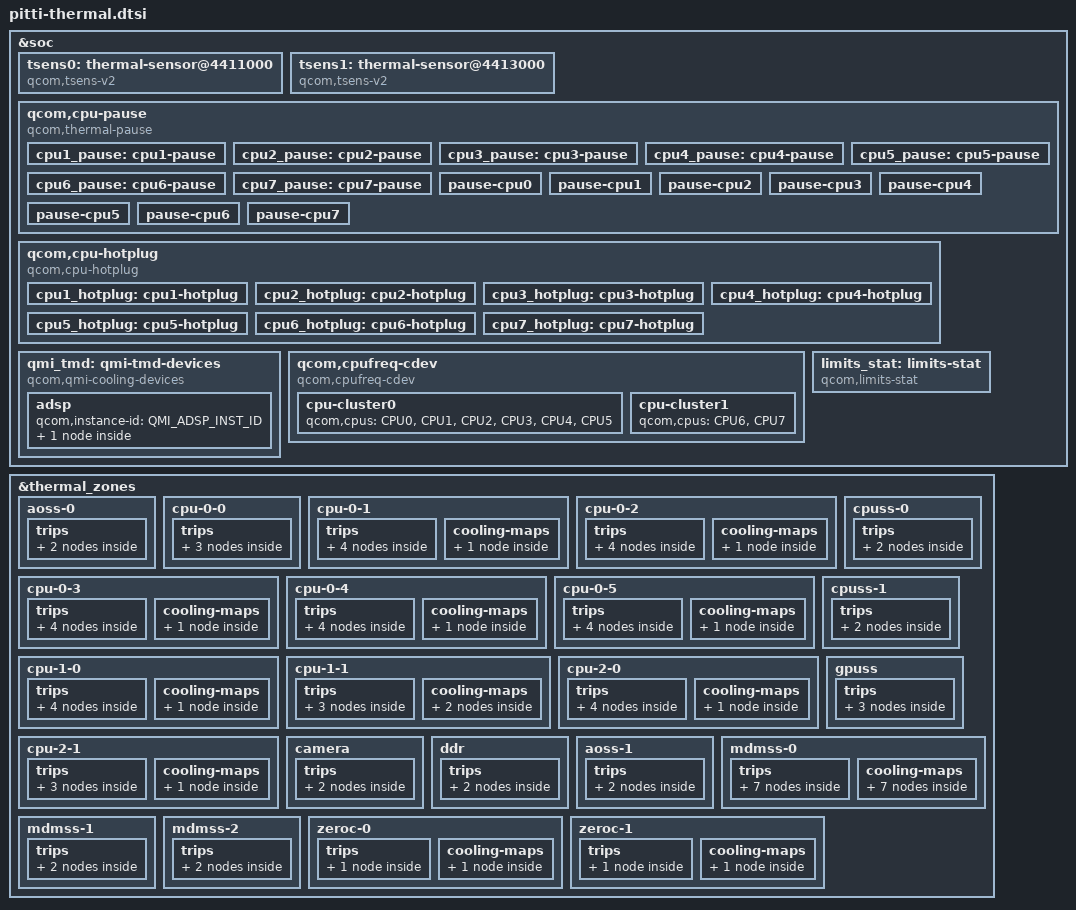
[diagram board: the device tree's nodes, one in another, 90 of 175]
#include <dt-bindings/thermal/thermal_qti.h>

&soc {
	tsens0: thermal-sensor@4411000 {
		compatible = "qcom,tsens-v2";
		reg = <0x04411000 0x1ff>, /* TM */
			<0x04410000 0x1ff>; /* SROT */
		#qcom,sensors = <16>;
		interrupts = <GIC_SPI 275 IRQ_TYPE_LEVEL_HIGH>,
				<GIC_SPI 190 IRQ_TYPE_LEVEL_HIGH>,
				<GIC_SPI 314 IRQ_TYPE_LEVEL_HIGH>;
		interrupt-names = "uplow",
				"critical",
				"cold";
		#thermal-sensor-cells = <1>;
	};

	tsens1: thermal-sensor@4413000 {
		compatible = "qcom,tsens-v2";
		reg = <0x04413000 0x1ff>, /* TM */
			<0x04412000 0x1ff>; /* SROT */
		#qcom,sensors = <4>;
		interrupts = <GIC_SPI 293 IRQ_TYPE_LEVEL_HIGH>,
				<GIC_SPI 316 IRQ_TYPE_LEVEL_HIGH>,
				<GIC_SPI 315 IRQ_TYPE_LEVEL_HIGH>;
		interrupt-names = "uplow",
			"critical",
			"cold";
		#thermal-sensor-cells = <1>;
	};

	qcom,cpu-pause {
		compatible = "qcom,thermal-pause";

		cpu1_pause: cpu1-pause {
			qcom,cpus = <&CPU1>;
			qcom,cdev-alias = "thermal-pause-2";
			#cooling-cells = <2>;
		};

		cpu2_pause: cpu2-pause {
			qcom,cpus = <&CPU2>;
			qcom,cdev-alias = "thermal-pause-4";
			#cooling-cells = <2>;
		};

		cpu3_pause: cpu3-pause {
			qcom,cpus = <&CPU3>;
			qcom,cdev-alias = "thermal-pause-8";
			#cooling-cells = <2>;
		};

		cpu4_pause: cpu4-pause {
			qcom,cpus = <&CPU4>;
			qcom,cdev-alias = "thermal-pause-10";
			#cooling-cells = <2>;
		};

		cpu5_pause: cpu5-pause {
			qcom,cpus = <&CPU5>;
			qcom,cdev-alias = "thermal-pause-20";
			#cooling-cells = <2>;
		};

		cpu6_pause: cpu6-pause {
			qcom,cpus = <&CPU6>;
			qcom,cdev-alias = "thermal-pause-40";
			#cooling-cells = <2>;
		};

		cpu7_pause: cpu7-pause {
			qcom,cpus = <&CPU7>;
			qcom,cdev-alias = "thermal-pause-80";
			#cooling-cells = <2>;
		};

		/* Thermal-engine cooling devices */
		pause-cpu0 {
			qcom,cpus = <&CPU0>;
			qcom,cdev-alias = "pause-cpu0";
		};

		pause-cpu1 {
			qcom,cpus = <&CPU1>;
			qcom,cdev-alias = "pause-cpu1";
		};

		pause-cpu2 {
			qcom,cpus = <&CPU2>;
			qcom,cdev-alias = "pause-cpu2";
		};

		pause-cpu3 {
			qcom,cpus = <&CPU3>;
			qcom,cdev-alias = "pause-cpu3";
		};

		pause-cpu4 {
			qcom,cpus = <&CPU4>;
			qcom,cdev-alias = "pause-cpu4";
		};

		pause-cpu5 {
			qcom,cpus = <&CPU5>;
			qcom,cdev-alias = "pause-cpu5";
		};

		pause-cpu6 {
			qcom,cpus = <&CPU6>;
			qcom,cdev-alias = "pause-cpu6";
		};

		pause-cpu7 {
			qcom,cpus = <&CPU7>;
			qcom,cdev-alias = "pause-cpu7";
		};
	};

	qcom,cpu-hotplug {
		compatible = "qcom,cpu-hotplug";

		cpu1_hotplug: cpu1-hotplug {
			qcom,cpu = <&CPU1>;
			qcom,cdev-alias = "cpu-hotplug1";
			#cooling-cells = <2>;
		};

		cpu2_hotplug: cpu2-hotplug {
			qcom,cpu = <&CPU2>;
			qcom,cdev-alias = "cpu-hotplug2";
			#cooling-cells = <2>;
		};

		cpu3_hotplug: cpu3-hotplug {
			qcom,cpu = <&CPU3>;
			qcom,cdev-alias = "cpu-hotplug3";
			#cooling-cells = <2>;
		};

		cpu4_hotplug: cpu4-hotplug {
			qcom,cpu = <&CPU4>;
			qcom,cdev-alias = "cpu-hotplug4";
			#cooling-cells = <2>;
		};

		cpu5_hotplug: cpu5-hotplug {
			qcom,cpu = <&CPU5>;
			qcom,cdev-alias = "cpu-hotplug5";
			#cooling-cells = <2>;
		};

		cpu6_hotplug: cpu6-hotplug {
			qcom,cpu = <&CPU6>;
			qcom,cdev-alias = "cpu-hotplug6";
			#cooling-cells = <2>;
		};

		cpu7_hotplug: cpu7-hotplug {
			qcom,cpu = <&CPU7>;
			qcom,cdev-alias = "cpu-hotplug7";
			#cooling-cells = <2>;
		};
	};

	qmi_tmd: qmi-tmd-devices {
		compatible = "qcom,qmi-cooling-devices";
		adsp {
			qcom,instance-id = <QMI_ADSP_INST_ID>;

			adsp_vdd: adsp_vdd {
				qcom,qmi-dev-name = "cpuv_restriction_cold";
				#cooling-cells = <2>;
			};
		};
	};

	qcom,cpufreq-cdev {
		compatible = "qcom,cpufreq-cdev";
		cpu-cluster0 {
			qcom,cpus = <&CPU0 &CPU1 &CPU2 &CPU3 &CPU4 &CPU5>;
		};

		cpu-cluster1 {
			qcom,cpus = <&CPU6 &CPU7>;
		};
	};

	limits_stat: limits-stat {
		compatible = "qcom,limits-stat";
		qcom,limits-stat-sensor-names = "aoss-0", "cpu-0-0", "cpu-0-1",
						"cpu-0-2", "cpu-0-3", "cpu-0-4",
						"cpu-0-5", "cpuss-0", "cpuss-1",
						"cpu-1-0", "cpu-1-1", "cpu-2-0",
						"cpu-2-1", "gpuss", "camera",
						"ddr", "aoss-1", "mdmss-0", "mdmss-1",
						"mdmss-2";
	};
};

#include "pitti-thermal-modem.dtsi"

&thermal_zones {
	aoss-0 {
		polling-delay-passive = <0>;
		polling-delay = <0>;
		thermal-sensors = <&tsens0 0>;
		trips {
			thermal-engine-config {
				temperature = <125000>;
				hysteresis = <1000>;
				type = "passive";
			};

			reset-mon-cfg {
				temperature = <115000>;
				hysteresis = <5000>;
				type = "passive";
			};
		};
	};

	cpu-0-0 {
		polling-delay-passive = <0>;
		polling-delay = <0>;
		thermal-sensors = <&tsens0 1>;
		trips {
			thermal-engine-config {
				temperature = <125000>;
				hysteresis = <1000>;
				type = "passive";
			};

			thermal-hal-config {
				temperature = <125000>;
				hysteresis = <1000>;
				type = "passive";
			};

			reset-mon-cfg {
				temperature = <115000>;
				hysteresis = <5000>;
				type = "passive";
			};
		};
	};

	cpu-0-1 {
		polling-delay-passive = <0>;
		polling-delay = <0>;
		thermal-sensors = <&tsens0 2>;
		trips {
			thermal-engine-config {
				temperature = <125000>;
				hysteresis = <1000>;
				type = "passive";
			};

			thermal-hal-config {
				temperature = <125000>;
				hysteresis = <1000>;
				type = "passive";
			};

			reset-mon-cfg {
				temperature = <115000>;
				hysteresis = <5000>;
				type = "passive";
			};

			cpu01_config: cpu01-config {
				temperature = <110000>;
				hysteresis = <10000>;
				type = "passive";
			};
		};

		cooling-maps {
			cpu01_cdev {
				trip = <&cpu01_config>;
				cooling-device = <&cpu1_pause 1 1>;
			};
		};
	};

	cpu-0-2 {
		polling-delay-passive = <0>;
		polling-delay = <0>;
		thermal-sensors = <&tsens0 3>;
		trips {
			thermal-engine-config {
				temperature = <125000>;
				hysteresis = <1000>;
				type = "passive";
			};

			thermal-hal-config {
				temperature = <125000>;
				hysteresis = <1000>;
				type = "passive";
			};

			reset-mon-cfg {
				temperature = <115000>;
				hysteresis = <5000>;
				type = "passive";
			};

			cpu02_config: cpu02-config {
				temperature = <110000>;
				hysteresis = <10000>;
				type = "passive";
			};
		};

		cooling-maps {
			cpu02_cdev {
				trip = <&cpu02_config>;
				cooling-device = <&cpu2_pause 1 1>;
			};
		};
	};

	cpu-0-3 {
		polling-delay-passive = <0>;
		polling-delay = <0>;
		thermal-sensors = <&tsens0 4>;
		trips {
			thermal-engine-config {
				temperature = <125000>;
				hysteresis = <1000>;
				type = "passive";
			};

			thermal-hal-config {
				temperature = <125000>;
				hysteresis = <1000>;
				type = "passive";
			};

			reset-mon-cfg {
				temperature = <115000>;
				hysteresis = <5000>;
				type = "passive";
			};

			cpu03_config: cpu03-config {
				temperature = <110000>;
				hysteresis = <10000>;
				type = "passive";
			};
		};

		cooling-maps {
			cpu03_cdev {
				trip = <&cpu03_config>;
				cooling-device = <&cpu3_pause 1 1>;
			};
		};
	};

	cpu-0-4 {
		polling-delay-passive = <0>;
		polling-delay = <0>;
		thermal-sensors = <&tsens0 5>;
		trips {
			thermal-engine-config {
				temperature = <125000>;
				hysteresis = <1000>;
				type = "passive";
			};

			thermal-hal-config {
				temperature = <125000>;
				hysteresis = <1000>;
				type = "passive";
			};

			reset-mon-cfg {
				temperature = <115000>;
				hysteresis = <5000>;
				type = "passive";
			};

			cpu04_config: cpu04-config {
				temperature = <110000>;
				hysteresis = <10000>;
				type = "passive";
			};
		};

		cooling-maps {
			cpu04_cdev {
				trip = <&cpu04_config>;
				cooling-device = <&cpu4_pause 1 1>;
			};
		};
	};

	cpu-0-5 {
		polling-delay-passive = <0>;
		polling-delay = <0>;
		thermal-sensors = <&tsens0 6>;
		trips {
			thermal-engine-config {
				temperature = <125000>;
				hysteresis = <1000>;
				type = "passive";
			};

			thermal-hal-config {
				temperature = <125000>;
				hysteresis = <1000>;
				type = "passive";
			};

			reset-mon-cfg {
				temperature = <115000>;
				hysteresis = <5000>;
				type = "passive";
			};

			cpu05_config: cpu05-config {
				temperature = <110000>;
				hysteresis = <10000>;
				type = "passive";
			};
		};

		cooling-maps {
			cpu05_cdev {
				trip = <&cpu05_config>;
				cooling-device = <&cpu5_pause 1 1>;
			};
		};
	};

	cpuss-0 {
		polling-delay-passive = <0>;
		polling-delay = <0>;
		thermal-sensors = <&tsens0 7>;
		trips {
			thermal-engine-config {
				temperature = <125000>;
				hysteresis = <1000>;
				type = "passive";
			};

			reset-mon-cfg {
				temperature = <115000>;
				hysteresis = <5000>;
				type = "passive";
			};
		};
	};

	cpuss-1 {
		polling-delay-passive = <0>;
		polling-delay = <0>;
		thermal-sensors = <&tsens0 8>;
		trips {
			thermal-engine-config {
				temperature = <125000>;
				hysteresis = <1000>;
				type = "passive";
			};

			reset-mon-cfg {
				temperature = <115000>;
				hysteresis = <5000>;
				type = "passive";
			};
		};
	};

	cpu-1-0 {
		polling-delay-passive = <0>;
		polling-delay = <0>;
		thermal-sensors = <&tsens0 9>;
		trips {
			thermal-engine-config {
				temperature = <125000>;
				hysteresis = <1000>;
				type = "passive";
			};

			thermal-hal-config {
				temperature = <125000>;
				hysteresis = <1000>;
				type = "passive";
			};

			reset-mon-cfg {
				temperature = <115000>;
				hysteresis = <5000>;
				type = "passive";
			};

			cpu10_config: cpu10-config {
				temperature = <110000>;
				hysteresis = <10000>;
				type = "passive";
			};
		};

		cooling-maps {
			cpu10_cdev {
				trip = <&cpu10_config>;
				cooling-device = <&cpu6_pause 1 1>;
			};
		};
	};

	cpu-1-1 {
		polling-delay-passive = <0>;
		polling-delay = <0>;
		thermal-sensors = <&tsens0 10>;
		trips {
			thermal-engine-config {
				temperature = <125000>;
				hysteresis = <1000>;
				type = "passive";
			};

			reset-mon-cfg {
				temperature = <115000>;
				hysteresis = <5000>;
				type = "passive";
			};

			cpu11_config: cpu11-config {
				temperature = <110000>;
				hysteresis = <10000>;
				type = "passive";
			};
		};

		cooling-maps {
			cpu11_cdev {
				trip = <&cpu11_config>;
				cooling-device = <&cpu6_pause 1 1>;
			};

			cpu11_cdev1 {
				trip = <&cpu11_config>;
				cooling-device = <&CPU6 7 7>;
			};
		};
	};

	cpu-2-0 {
		polling-delay-passive = <0>;
		polling-delay = <0>;
		thermal-sensors = <&tsens0 11>;
		trips {
			thermal-engine-config {
				temperature = <125000>;
				hysteresis = <1000>;
				type = "passive";
			};

			thermal-hal-config {
				temperature = <125000>;
				hysteresis = <1000>;
				type = "passive";
			};

			reset-mon-cfg {
				temperature = <115000>;
				hysteresis = <5000>;
				type = "passive";
			};

			cpu20_config: cpu20-config {
				temperature = <110000>;
				hysteresis = <10000>;
				type = "passive";
			};
		};

		cooling-maps {
			cpu20_cdev {
				trip = <&cpu20_config>;
				cooling-device = <&cpu7_pause 1 1>;
			};
		};
	};

	cpu-2-1 {
		polling-delay-passive = <0>;
		polling-delay = <0>;
		thermal-sensors = <&tsens0 12>;
		trips {
			thermal-engine-config {
				temperature = <125000>;
				hysteresis = <1000>;
				type = "passive";
			};

			reset-mon-cfg {
				temperature = <115000>;
				hysteresis = <5000>;
				type = "passive";
			};

			cpu21_config: cpu21-config {
				temperature = <110000>;
				hysteresis = <10000>;
				type = "passive";
			};
		};

		cooling-maps {
			cpu13_cdev {
				trip = <&cpu21_config>;
				cooling-device = <&cpu7_pause 1 1>;
			};
		};
	};

	gpuss {
		polling-delay-passive = <10>;
		polling-delay = <0>;
		thermal-sensors = <&tsens0 13>;
		trips {
			thermal-engine-config {
				temperature = <125000>;
				hysteresis = <1000>;
				type = "passive";
			};

			thermal-hal-config {
				temperature = <125000>;
				hysteresis = <1000>;
				type = "passive";
			};

			reset-mon-cfg {
				temperature = <115000>;
				hysteresis = <5000>;
				type = "passive";
			};
		};
	};

	camera {
		polling-delay-passive = <0>;
		polling-delay = <0>;
		thermal-sensors = <&tsens0 14>;
		trips {
			thermal-engine-config {
				temperature = <125000>;
				hysteresis = <1000>;
				type = "passive";
			};

			reset-mon-cfg {
				temperature = <115000>;
				hysteresis = <5000>;
				type = "passive";
			};
		};
	};

	ddr {
		polling-delay-passive = <10>;
		polling-delay = <0>;
		thermal-sensors = <&tsens0 15>;
		trips {
			thermal-engine-config {
				temperature = <125000>;
				hysteresis = <1000>;
				type = "passive";
			};

			reset-mon-cfg {
				temperature = <115000>;
				hysteresis = <5000>;
				type = "passive";
			};
		};
	};

	aoss-1 {
		polling-delay-passive = <0>;
		polling-delay = <0>;
		thermal-sensors = <&tsens1 0>;
		trips {
			thermal-engine-config {
				temperature = <125000>;
				hysteresis = <1000>;
				type = "passive";
			};

			reset-mon-cfg {
				temperature = <115000>;
				hysteresis = <5000>;
				type = "passive";
			};
		};
	};

	mdmss-0 {
		polling-delay-passive = <0>;
		polling-delay = <0>;
		thermal-sensors = <&tsens1 1>;
		trips {
			thermal-engine-config {
				temperature = <125000>;
				hysteresis = <1000>;
				type = "passive";
			};

			reset-mon-cfg {
				temperature = <115000>;
				hysteresis = <5000>;
				type = "passive";
			};

			mdmss0_config0: mdmss0-config0 {
				temperature = <105000>;
				hysteresis = <3000>;
				type = "active";
			};

			mdmss0_config1: mdmss0-config1 {
				temperature = <102000>;
				hysteresis = <2000>;
				type = "active";
			};

			mdmss0_config2: mdmss0-config2 {
				temperature = <100000>;
				hysteresis = <2000>;
				type = "active";
			};

			mdmss0_config3: mdmss0-config3 {
				temperature = <98000>;
				hysteresis = <3000>;
				type = "active";
			};

			mdmss0_config4: mdmss0-config4 {
				temperature = <95000>;
				hysteresis = <3000>;
				type = "active";
			};
		};

		cooling-maps {
			lte_cdev0 {
				trip = <&mdmss0_config0>;
				cooling-device = <&modem_lte_dsc 255 255>;
			};

			nr_cdev0 {
				trip = <&mdmss0_config0>;
				cooling-device = <&modem_nr_dsc 255 255>;
			};

			nr_cdev1 {
				trip = <&mdmss0_config1>;
				cooling-device = <&modem_nr_dsc 254 254>;
			};

			nr_cdev2 {
				trip = <&mdmss0_config2>;
				cooling-device = <&modem_nr_dsc 3 3>;
			};

			nr_cdev4 {
				trip = <&mdmss0_config3>;
				cooling-device = <&modem_nr_dsc 2 2>;
			};

			lte_cdev1 {
				trip = <&mdmss0_config4>;
				cooling-device = <&modem_lte_dsc 1 1>;
			};

			nr_cdev5 {
				trip = <&mdmss0_config4>;
				cooling-device = <&modem_nr_dsc 1 1>;
			};
		};
	};

	mdmss-1 {
		polling-delay-passive = <0>;
		polling-delay = <0>;
		thermal-sensors = <&tsens1 2>;
		trips {
			thermal-engine-config {
				temperature = <125000>;
				hysteresis = <1000>;
				type = "passive";
			};

			reset-mon-cfg {
				temperature = <115000>;
				hysteresis = <5000>;
				type = "passive";
			};
		};
	};

	mdmss-2 {
		polling-delay-passive = <0>;
		polling-delay = <0>;
		thermal-sensors = <&tsens1 3>;
		trips {
			thermal-engine-config {
				temperature = <125000>;
				hysteresis = <1000>;
				type = "passive";
			};

			reset-mon-cfg {
				temperature = <115000>;
				hysteresis = <5000>;
				type = "passive";
			};
		};
	};

	zeroc-0 {
		polling-delay-passive = <0>;
		polling-delay = <0>;
		thermal-sensors = <&tsens0 16>;

		trips {
			zeroc_0_trip: active-config0 {
				temperature = <1>;
				hysteresis = <1>;
				type = "passive";
			};
		};

		cooling-maps {
			adsp_vdd_cdev {
				trip = <&zeroc_0_trip>;
				cooling-device = <&adsp_vdd 1 1>;
			};
		};
	};

	zeroc-1 {
		polling-delay-passive = <0>;
		polling-delay = <0>;
		thermal-sensors = <&tsens1 16>;

		trips {
			zeroc_1_trip: active-config0 {
				temperature = <1>;
				hysteresis = <1>;
				type = "passive";
			};
		};

		cooling-maps {
			adsp_vdd_cdev {
				trip = <&zeroc_1_trip>;
				cooling-device = <&adsp_vdd 1 1>;
			};
		};
	};
};
